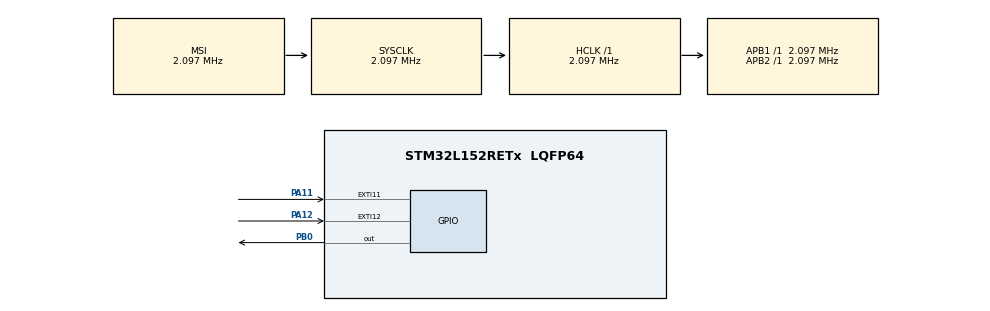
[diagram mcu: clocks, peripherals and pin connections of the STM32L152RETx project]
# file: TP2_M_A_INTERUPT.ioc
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Mcu.Family=STM32L1
Mcu.Name=STM32L152RETx
Mcu.Package=LQFP64
NVIC.EXTI15_10_IRQn=true\:0\:0\:false\:false\:true\:true\:true\:true
NVIC.PriorityGroup=NVIC_PRIORITYGROUP_4
PA11.Signal=GPXTI11
PA12.Signal=GPXTI12
PB0.Signal=GPIO_Output
ProjectManager.HeapSize=0x200
ProjectManager.StackSize=0x400
ProjectManager.TargetToolchain=STM32CubeIDE
RCC.AHBFreq_Value=2097000
RCC.APB1Freq_Value=2097000
RCC.APB2Freq_Value=2097000
RCC.HSE_VALUE=24000000
RCC.HSI_VALUE=16000000
RCC.LSE_VALUE=32768
RCC.MSI_VALUE=2097000
RCC.SYSCLKFreq_VALUE=2097000
RCC.VCOOutputFreq_Value=48000000
board=custom

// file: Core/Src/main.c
/* USER CODE BEGIN Header */
/**
  ******************************************************************************
  * @file           : main.c
  * @brief          : Main program body
  ******************************************************************************
  * @attention
  *
  * Copyright (c) 2025 STMicroelectronics.
  * All rights reserved.
  *
  * This software is licensed under terms that can be found in the LICENSE file
  * in the root directory of this software component.
  * If no LICENSE file comes with this software, it is provided AS-IS.
  *
  ******************************************************************************
  */
/* USER CODE END Header */
#include "main.h"

void SystemClock_Config(void);
static void MX_GPIO_Init(void);

/* USER CODE BEGIN 0 */
void init_ports_LED(void){
	GPIOB->ODR |= (1<<0);
}

void init_ports_BP(void){
	GPIOA->MODER &= ~(1<<11);
	GPIOA->MODER &= ~(1<<12);
}

void allume_LED(void){
	GPIOB->ODR |= (1<<0);
}

void eteint_LED(void){
	GPIOB->ODR &= ~(1<<0);
}

uint8_t clignotant = 0;
/* USER CODE END 0 */

int main(void)
{

  /* MCU Configuration--------------------------------------------------------*/

  /* Reset of all peripherals, Initializes the Flash interface and the Systick. */
  HAL_Init();

  /* Configure the system clock */
  SystemClock_Config();

  /* Initialize all configured peripherals */
  MX_GPIO_Init();

  /* Infinite loop */
  while (1)
  {

    /* USER CODE BEGIN 3 */
	  if (clignotant == 1){
		  allume_LED();
		  HAL_Delay(500);
		  eteint_LED();
		  HAL_Delay(500);
	  }
  }
  /* USER CODE END 3 */
}

void SystemClock_Config(void)
{
  RCC_OscInitTypeDef RCC_OscInitStruct = {0};
  RCC_ClkInitTypeDef RCC_ClkInitStruct = {0};

  /** Configure the main internal regulator output voltage
  */
  __HAL_PWR_VOLTAGESCALING_CONFIG(PWR_REGULATOR_VOLTAGE_SCALE1);

  /** Initializes the RCC Oscillators according to the specified parameters
  * in the RCC_OscInitTypeDef structure.
  */
  RCC_OscInitStruct.OscillatorType = RCC_OSCILLATORTYPE_MSI;
  RCC_OscInitStruct.MSIState = RCC_MSI_ON;
  RCC_OscInitStruct.MSICalibrationValue = 0;
  RCC_OscInitStruct.MSIClockRange = RCC_MSIRANGE_5;
  RCC_OscInitStruct.PLL.PLLState = RCC_PLL_NONE;
  if (HAL_RCC_OscConfig(&RCC_OscInitStruct) != HAL_OK)
  {
    Error_Handler();
  }

  /** Initializes the CPU, AHB and APB buses clocks
  */
  RCC_ClkInitStruct.ClockType = RCC_CLOCKTYPE_HCLK|RCC_CLOCKTYPE_SYSCLK
                              |RCC_CLOCKTYPE_PCLK1|RCC_CLOCKTYPE_PCLK2;
  RCC_ClkInitStruct.SYSCLKSource = RCC_SYSCLKSOURCE_MSI;
  RCC_ClkInitStruct.AHBCLKDivider = RCC_SYSCLK_DIV1;
  RCC_ClkInitStruct.APB1CLKDivider = RCC_HCLK_DIV1;
  RCC_ClkInitStruct.APB2CLKDivider = RCC_HCLK_DIV1;

  if (HAL_RCC_ClockConfig(&RCC_ClkInitStruct, FLASH_LATENCY_0) != HAL_OK)
  {
    Error_Handler();
  }
}

static void MX_GPIO_Init(void)
{
  GPIO_InitTypeDef GPIO_InitStruct = {0};

  /* GPIO Ports Clock Enable */
  __HAL_RCC_GPIOB_CLK_ENABLE();
  __HAL_RCC_GPIOA_CLK_ENABLE();

  /*Configure GPIO pin Output Level */
  HAL_GPIO_WritePin(GPIOB, GPIO_PIN_0, GPIO_PIN_RESET);

  /*Configure GPIO pin : PB0 */
  GPIO_InitStruct.Pin = GPIO_PIN_0;
  GPIO_InitStruct.Mode = GPIO_MODE_OUTPUT_PP;
  GPIO_InitStruct.Pull = GPIO_NOPULL;
  GPIO_InitStruct.Speed = GPIO_SPEED_FREQ_LOW;
  HAL_GPIO_Init(GPIOB, &GPIO_InitStruct);

  /*Configure GPIO pins : PA11 PA12 */
  GPIO_InitStruct.Pin = GPIO_PIN_11|GPIO_PIN_12;
  GPIO_InitStruct.Mode = GPIO_MODE_IT_RISING;
  GPIO_InitStruct.Pull = GPIO_NOPULL;
  HAL_GPIO_Init(GPIOA, &GPIO_InitStruct);

  /* EXTI interrupt init*/
  HAL_NVIC_SetPriority(EXTI15_10_IRQn, 0, 0);
  HAL_NVIC_EnableIRQ(EXTI15_10_IRQn);

}

/* USER CODE BEGIN 4 */
void HAL_GPIO_EXTI_Callback(uint16_t GPIO_Pin){
	if (GPIO_Pin == (1<<11)){
		clignotant = 1;
	} else {
		clignotant = 0;
	}
}
/* USER CODE END 4 */

void Error_Handler(void)
{
  __disable_irq();
  while (1)
  {
  }
}
